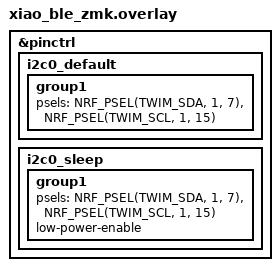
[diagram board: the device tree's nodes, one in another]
&pinctrl {
   i2c0_default: i2c0_default {
     group1 {
        psels = <NRF_PSEL(TWIM_SDA, 1, 7)>,
                <NRF_PSEL(TWIM_SCL, 1, 15)>;
     };
  };

  i2c0_sleep: i2c0_sleep {
     group1 {
        psels = <NRF_PSEL(TWIM_SDA, 1, 7)>,
                <NRF_PSEL(TWIM_SCL, 1, 15)>;
        low-power-enable;
     };
  };
};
